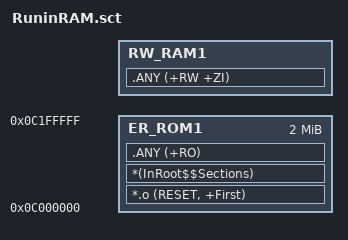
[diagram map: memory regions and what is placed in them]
; *************************************************************
; *** Scatter-Loading Description File generated by uVision ***
; *************************************************************
; Run in RAM

LR_ROM1 0x0C000000         
{                                 ; load region
  ER_ROM1 0x0C000000 0x0200000  
  {                               ; load address = execution address
   *.o (RESET, +First)
   *(InRoot$$Sections)
   .ANY (+RO)
  }
  RW_RAM1 +0  
  {                               ; RW data
   .ANY (+RW +ZI)
  }
}

